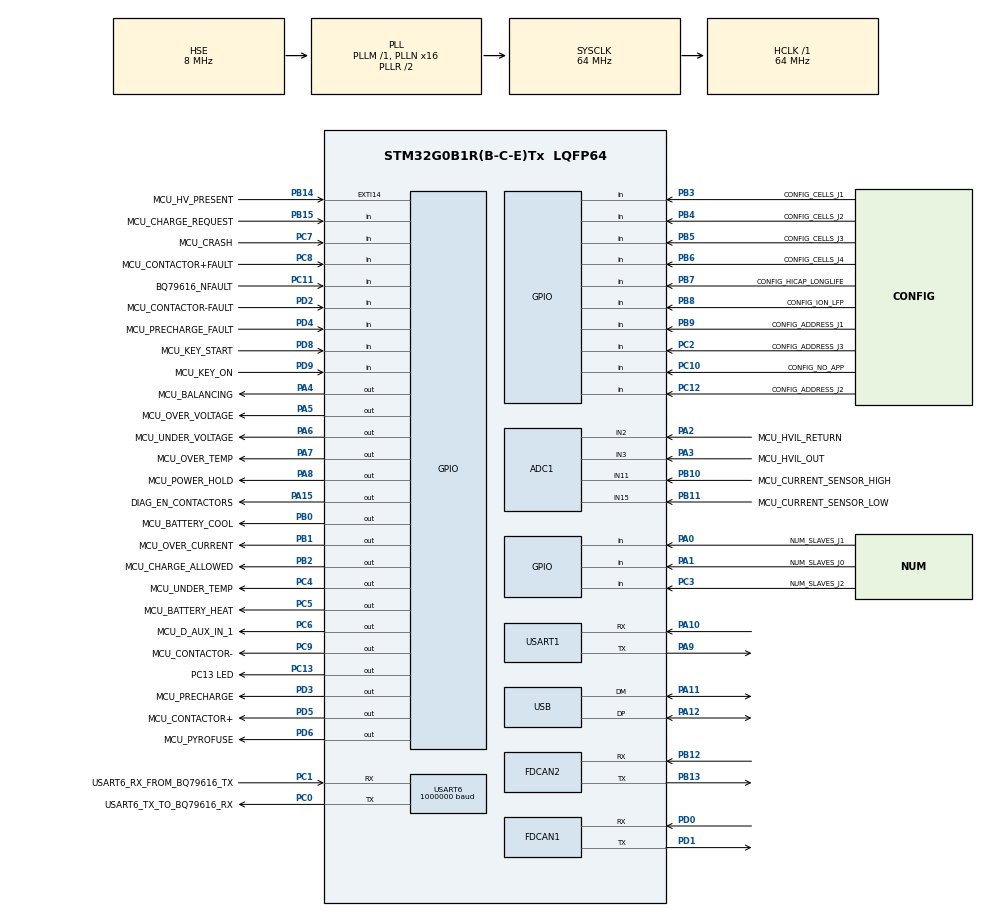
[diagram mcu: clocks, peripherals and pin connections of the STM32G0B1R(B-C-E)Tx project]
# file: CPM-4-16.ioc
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ADC1.NbrOfConversion=1
ADC1.NbrOfConversionFlag=0
ADC1.SelectedChannel=ADC_CHANNEL_2|ADC_CHANNEL_3|ADC_CHANNEL_11|ADC_CHANNEL_15
ADC1.Sequencer=NOT_FULLY_CONFIGURABLE
ADC1.master=1
Dma.Request0=USART1_TX
Dma.USART1_TX.0.Direction=DMA_MEMORY_TO_PERIPH
Dma.USART1_TX.0.EventEnable=DISABLE
Dma.USART1_TX.0.Instance=DMA1_Channel1
Dma.USART1_TX.0.MemDataAlignment=DMA_MDATAALIGN_BYTE
Dma.USART1_TX.0.MemInc=DMA_MINC_ENABLE
Dma.USART1_TX.0.Mode=DMA_NORMAL
Dma.USART1_TX.0.PeriphDataAlignment=DMA_PDATAALIGN_BYTE
Dma.USART1_TX.0.PeriphInc=DMA_PINC_DISABLE
Dma.USART1_TX.0.Polarity=HAL_DMAMUX_REQ_GEN_RISING
Dma.USART1_TX.0.Priority=DMA_PRIORITY_LOW
Dma.USART1_TX.0.RequestNumber=1
Dma.USART1_TX.0.SignalID=NONE
Dma.USART1_TX.0.SyncEnable=DISABLE
Dma.USART1_TX.0.SyncPolarity=HAL_DMAMUX_SYNC_NO_EVENT
Dma.USART1_TX.0.SyncRequestNumber=1
Dma.USART1_TX.0.SyncSignalID=NONE
FDCAN1.AutoRetransmission=ENABLE
FDCAN1.CalculateBaudRateNominal=500000
FDCAN1.CalculateTimeBitNominal=2000
FDCAN1.CalculateTimeQuantumNominal=125.0
FDCAN1.NominalPrescaler=8
FDCAN1.NominalSyncJumpWidth=2
FDCAN1.NominalTimeSeg1=13
FDCAN1.NominalTimeSeg2=2
FDCAN1.StdFiltersNbr=1
FDCAN2.CalculateBaudRateNominal=1333333
FDCAN2.CalculateTimeBitNominal=750
FDCAN2.CalculateTimeQuantumNominal=250.0
Mcu.Family=STM32G0
Mcu.Name=STM32G0B1R(B-C-E)Tx
Mcu.Package=LQFP64
NVIC.DMA1_Channel1_IRQn=true\:0\:0\:false\:false\:true\:false\:true\:true
NVIC.TIM2_IRQn=true\:3\:0\:true\:false\:true\:true\:true\:true
NVIC.TIM3_TIM4_IRQn=true\:3\:0\:true\:false\:true\:true\:true\:true
NVIC.USB_UCPD1_2_IRQn=true\:0\:0\:false\:false\:true\:true\:true\:true
NVIC.USART1_IRQn=true\:0\:0\:false\:false\:true\:true\:true\:true
PA0.GPIO_Label=NUM_SLAVES_J1
PA0.GPIO_PuPd=GPIO_PULLDOWN
PA0.Signal=GPIO_Input
PA1.GPIO_Label=NUM_SLAVES_J0
PA1.GPIO_PuPd=GPIO_PULLDOWN
PA1.Signal=GPIO_Input
PA10.Mode=Asynchronous
PA10.Signal=USART1_RX
PA11\ [PA9].Mode=Device
PA11\ [PA9].Signal=USB_DM
PA12\ [PA10].Mode=Device
PA12\ [PA10].Signal=USB_DP
PA13.Mode=Serial_Wire
PA13.Signal=SYS_SWDIO
PA14-BOOT0.Mode=Serial_Wire
PA14-BOOT0.Signal=SYS_SWCLK
PA15.GPIO_Label=DIAG_EN_CONTACTORS
PA15.Signal=GPIO_Output
PA2.GPIO_Label=MCU_HVIL_RETURN
PA2.Mode=IN2
PA2.Signal=ADC1_IN2
PA3.GPIO_Label=MCU_HVIL_OUT
PA3.Mode=IN3
PA3.Signal=ADC1_IN3
PA4.GPIO_Label=MCU_BALANCING
PA4.Signal=GPIO_Output
PA5.GPIO_Label=MCU_OVER_VOLTAGE
PA5.Signal=GPIO_Output
PA6.GPIO_Label=MCU_UNDER_VOLTAGE
PA6.Signal=GPIO_Output
PA7.GPIO_Label=MCU_OVER_TEMP
PA7.Signal=GPIO_Output
PA8.GPIO_Label=MCU_POWER_HOLD
PA8.Signal=GPIO_Output
PA9.Mode=Asynchronous
PA9.Signal=USART1_TX
PB0.GPIO_Label=MCU_BATTERY_COOL
PB0.Signal=GPIO_Output
PB1.GPIO_Label=MCU_OVER_CURRENT
PB1.Signal=GPIO_Output
PB10.GPIO_Label=MCU_CURRENT_SENSOR_HIGH
PB10.Mode=IN11
PB10.Signal=ADC1_IN11
PB11.GPIO_Label=MCU_CURRENT_SENSOR_LOW
PB11.Mode=IN15
PB11.Signal=ADC1_IN15
PB12.Mode=FDCAN_Activate
PB12.Signal=FDCAN2_RX
PB13.Mode=FDCAN_Activate
PB13.Signal=FDCAN2_TX
PB14.GPIO_Label=MCU_HV_PRESENT
PB14.Signal=GPXTI14
PB15.GPIO_Label=MCU_CHARGE_REQUEST
PB15.Signal=GPIO_Input
PB2.GPIO_Label=MCU_CHARGE_ALLOWED
PB2.Signal=GPIO_Output
PB3.GPIO_Label=CONFIG_CELLS_J1
PB3.GPIO_PuPd=GPIO_PULLDOWN
PB3.Signal=GPIO_Input
PB4.GPIO_Label=CONFIG_CELLS_J2
PB4.GPIO_PuPd=GPIO_PULLDOWN
PB4.Signal=GPIO_Input
PB5.GPIO_Label=CONFIG_CELLS_J3
PB5.GPIO_PuPd=GPIO_PULLDOWN
PB5.Signal=GPIO_Input
PB6.GPIO_Label=CONFIG_CELLS_J4
PB6.GPIO_PuPd=GPIO_PULLDOWN
PB6.Signal=GPIO_Input
PB7.GPIO_Label=CONFIG_HICAP_LONGLIFE
PB7.GPIO_PuPd=GPIO_PULLDOWN
PB7.Signal=GPIO_Input
PB8.GPIO_Label=CONFIG_ION_LFP
PB8.GPIO_PuPd=GPIO_PULLDOWN
PB8.Signal=GPIO_Input
PB9.GPIO_Label=CONFIG_ADDRESS_J1
PB9.GPIO_PuPd=GPIO_PULLDOWN
PB9.Signal=GPIO_Input
PC0.GPIO_Label=USART6_TX_TO_BQ79616_RX
PC0.Mode=Asynchronous
PC0.Signal=USART6_TX
PC1.GPIO_Label=USART6_RX_FROM_BQ79616_TX
PC1.Mode=Asynchronous
PC1.Signal=USART6_RX
PC10.GPIO_Label=CONFIG_NO_APP
PC10.GPIO_PuPd=GPIO_PULLDOWN
PC10.Signal=GPIO_Input
PC11.GPIO_Label=BQ79616_NFAULT
PC11.GPIO_PuPd=GPIO_PULLDOWN
PC11.Signal=GPIO_Input
PC12.GPIO_Label=CONFIG_ADDRESS_J2
PC12.GPIO_PuPd=GPIO_PULLDOWN
PC12.Signal=GPIO_Input
PC13.GPIO_Label=PC13 LED
PC13.Signal=GPIO_Output
PC14-OSC32_IN\ (PC14).Mode=LSE-External-Oscillator
PC14-OSC32_IN\ (PC14).Signal=RCC_OSC32_IN
PC15-OSC32_OUT\ (PC15).Mode=LSE-External-Oscillator
PC15-OSC32_OUT\ (PC15).Signal=RCC_OSC32_OUT
PC2.GPIO_Label=CONFIG_ADDRESS_J3
PC2.GPIO_Mode=GPIO_MODE_INPUT
PC2.GPIO_PuPd=GPIO_PULLDOWN
PC2.Signal=GPIO_Input
PC3.GPIO_Label=NUM_SLAVES_J2
PC3.GPIO_Mode=GPIO_MODE_INPUT
PC3.GPIO_PuPd=GPIO_PULLDOWN
PC3.Signal=GPIO_Input
PC4.GPIO_Label=MCU_UNDER_TEMP
PC4.Signal=GPIO_Output
PC5.GPIO_Label=MCU_BATTERY_HEAT
PC5.Signal=GPIO_Output
PC6.GPIO_Label=MCU_D_AUX_IN_1
PC6.Signal=GPIO_Output
PC7.GPIO_Label=MCU_CRASH
PC7.GPIO_Mode=GPIO_MODE_INPUT
PC7.GPIO_PuPd=GPIO_PULLDOWN
PC7.Signal=GPIO_Input
PC8.GPIO_Label=MCU_CONTACTOR+FAULT
PC8.GPIO_PuPd=GPIO_PULLUP
PC8.Signal=GPIO_Input
PC9.GPIO_Label=MCU_CONTACTOR-
PC9.Signal=GPIO_Output
PD0.Mode=FDCAN_Activate
PD0.Signal=FDCAN1_RX
PD1.Mode=FDCAN_Activate
PD1.Signal=FDCAN1_TX
PD2.GPIO_Label=MCU_CONTACTOR-FAULT
PD2.GPIO_PuPd=GPIO_PULLUP
PD2.Signal=GPIO_Input
PD3.GPIO_Label=MCU_PRECHARGE
PD3.Signal=GPIO_Output
PD4.GPIO_Label=MCU_PRECHARGE_FAULT
PD4.GPIO_PuPd=GPIO_PULLUP
PD4.Signal=GPIO_Input
PD5.GPIO_Label=MCU_CONTACTOR+
PD5.Signal=GPIO_Output
PD6.GPIO_Label=MCU_PYROFUSE
PD6.Signal=GPIO_Output
PD8.GPIO_Label=MCU_KEY_START
PD8.GPIO_PuPd=GPIO_PULLDOWN
PD8.Signal=GPIO_Input
PD9.GPIO_Label=MCU_KEY_ON
PD9.GPIO_PuPd=GPIO_PULLDOWN
PD9.Signal=GPIO_Input
PF0-OSC_IN\ (PF0).Mode=HSE-External-Oscillator
PF0-OSC_IN\ (PF0).Signal=RCC_OSC_IN
PF1-OSC_OUT\ (PF1).Mode=HSE-External-Oscillator
PF1-OSC_OUT\ (PF1).Signal=RCC_OSC_OUT
ProjectManager.HeapSize=0x200
ProjectManager.StackSize=0x400
ProjectManager.TargetToolchain=STM32CubeIDE
RCC.ADCFreq_Value=64000000
RCC.AHBFreq_Value=64000000
RCC.CortexFreq_Value=64000000
RCC.EXTERNAL_CLOCK_VALUE=48000
RCC.EnbaleCSS=true
RCC.FDCANCLockSelection=RCC_FDCANCLKSOURCE_PLL
RCC.HCLKFreq_Value=64000000
RCC.HSE_VALUE=8000000
RCC.HSI48_VALUE=48000000
RCC.HSI_VALUE=16000000
RCC.PLLN=16
RCC.PLLSourceVirtual=RCC_PLLSOURCE_HSE
RCC.SYSCLKFreq_VALUE=64000000
RCC.SYSCLKSource=RCC_SYSCLKSOURCE_PLLCLK
RCC.USBFreq_Value=48000000
RCC.VCOOutputFreq_Value=128000000
TIM2.Period=999
TIM2.Prescaler=63999
TIM3.Period=99
TIM3.Prescaler=6399
USART1.VirtualMode-Asynchronous=VM_ASYNC
USART6.BaudRate=1000000
USART6.VirtualMode-Asynchronous=VM_ASYNC
USB_DEVICE.CLASS_NAME_FS=CDC
USB_DEVICE.VirtualMode=Cdc
USB_DEVICE.VirtualModeFS=Cdc_FS
VP_SYS_VS_DBSignals.Mode=DisableDeadBatterySignals
VP_TIM2_VS_ClockSourceINT.Mode=Internal
VP_TIM3_VS_ClockSourceINT.Mode=Internal
VP_USB_DEVICE_VS_USB_DEVICE_CDC_FS.Mode=CDC_FS
board=custom

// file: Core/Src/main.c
/* USER CODE BEGIN Header */
/**
  ******************************************************************************
  * @file           : main.c
  * @brief          : Main program body
  ******************************************************************************
  * @attention
  *
  * Copyright (c) 2026 STMicroelectronics.
  * All rights reserved.
  *
  * This software is licensed under terms that can be found in the LICENSE file
  * in the root directory of this software component.
  * If no LICENSE file comes with this software, it is provided AS-IS.
  *
  ******************************************************************************
  */
/* USER CODE END Header */
#include "main.h"
#include "usb_device.h"

/* USER CODE BEGIN Includes */
#include "application.h"
#include "board.h"
/* USER CODE END Includes */

ADC_HandleTypeDef hadc1;

FDCAN_HandleTypeDef hfdcan1;
FDCAN_HandleTypeDef hfdcan2;

TIM_HandleTypeDef htim2;
TIM_HandleTypeDef htim3;

UART_HandleTypeDef huart1;
UART_HandleTypeDef huart6;
DMA_HandleTypeDef hdma_usart1_tx;

void SystemClock_Config(void);
static void MX_GPIO_Init(void);
static void MX_DMA_Init(void);
static void MX_FDCAN1_Init(void);
static void MX_FDCAN2_Init(void);
static void MX_USART1_UART_Init(void);
static void MX_ADC1_Init(void);
static void MX_USART6_UART_Init(void);
static void MX_TIM2_Init(void);
static void MX_TIM3_Init(void);

int main(void)
{

  /* MCU Configuration--------------------------------------------------------*/

  /* Reset of all peripherals, Initializes the Flash interface and the Systick. */
  HAL_Init();

  /* Configure the system clock */
  SystemClock_Config();

  /* Initialize all configured peripherals */
  MX_GPIO_Init();
  board_refresh_identity_from_jumpers();
  MX_DMA_Init();
  MX_FDCAN1_Init();
  MX_FDCAN2_Init();
  MX_USART1_UART_Init();
  MX_ADC1_Init();
  if (board_get_address() != BOARD_ADDR_MASTER)
  {
    MX_USART6_UART_Init();
  }
  MX_TIM2_Init();
  MX_TIM3_Init();
  MX_USB_Device_Init();
  /* USER CODE BEGIN 2 */
application_setup();

  /* USER CODE END 2 */

  /* Infinite loop */
  /* USER CODE BEGIN WHILE */
  while (1)
  {
	  application_loop();
    /* USER CODE END WHILE */

  }
}

void SystemClock_Config(void)
{
  RCC_OscInitTypeDef RCC_OscInitStruct = {0};
  RCC_ClkInitTypeDef RCC_ClkInitStruct = {0};

  /** Configure the main internal regulator output voltage
  */
  HAL_PWREx_ControlVoltageScaling(PWR_REGULATOR_VOLTAGE_SCALE1);

  /** Initializes the RCC Oscillators according to the specified parameters
  * in the RCC_OscInitTypeDef structure.
  */
  RCC_OscInitStruct.OscillatorType = RCC_OSCILLATORTYPE_HSE|RCC_OSCILLATORTYPE_HSI48;
  RCC_OscInitStruct.HSEState = RCC_HSE_ON;
  RCC_OscInitStruct.HSI48State = RCC_HSI48_ON;
  RCC_OscInitStruct.PLL.PLLState = RCC_PLL_ON;
  RCC_OscInitStruct.PLL.PLLSource = RCC_PLLSOURCE_HSE;
  RCC_OscInitStruct.PLL.PLLM = RCC_PLLM_DIV1;
  RCC_OscInitStruct.PLL.PLLN = 16;
  RCC_OscInitStruct.PLL.PLLP = RCC_PLLP_DIV2;
  RCC_OscInitStruct.PLL.PLLQ = RCC_PLLQ_DIV2;
  RCC_OscInitStruct.PLL.PLLR = RCC_PLLR_DIV2;
  if (HAL_RCC_OscConfig(&RCC_OscInitStruct) != HAL_OK)
  {
    Error_Handler();
  }

  /** Initializes the CPU, AHB and APB buses clocks
  */
  RCC_ClkInitStruct.ClockType = RCC_CLOCKTYPE_HCLK|RCC_CLOCKTYPE_SYSCLK
                              |RCC_CLOCKTYPE_PCLK1;
  RCC_ClkInitStruct.SYSCLKSource = RCC_SYSCLKSOURCE_PLLCLK;
  RCC_ClkInitStruct.AHBCLKDivider = RCC_SYSCLK_DIV1;
  RCC_ClkInitStruct.APB1CLKDivider = RCC_HCLK_DIV1;

  if (HAL_RCC_ClockConfig(&RCC_ClkInitStruct, FLASH_LATENCY_2) != HAL_OK)
  {
    Error_Handler();
  }

  /** Enables the Clock Security System
  */
  HAL_RCC_EnableCSS();
}

static void MX_ADC1_Init(void)
{

  ADC_ChannelConfTypeDef sConfig = {0};

  /** Configure the global features of the ADC (Clock, Resolution, Data Alignment and number of conversion)
  */
  hadc1.Instance = ADC1;
  hadc1.Init.ClockPrescaler = ADC_CLOCK_SYNC_PCLK_DIV2;
  hadc1.Init.Resolution = ADC_RESOLUTION_12B;
  hadc1.Init.DataAlign = ADC_DATAALIGN_RIGHT;
  hadc1.Init.ScanConvMode = ADC_SCAN_SEQ_FIXED;
  hadc1.Init.EOCSelection = ADC_EOC_SINGLE_CONV;
  hadc1.Init.LowPowerAutoWait = DISABLE;
  hadc1.Init.LowPowerAutoPowerOff = DISABLE;
  hadc1.Init.ContinuousConvMode = DISABLE;
  hadc1.Init.NbrOfConversion = 1;
  hadc1.Init.DiscontinuousConvMode = DISABLE;
  hadc1.Init.ExternalTrigConv = ADC_SOFTWARE_START;
  hadc1.Init.ExternalTrigConvEdge = ADC_EXTERNALTRIGCONVEDGE_NONE;
  hadc1.Init.DMAContinuousRequests = DISABLE;
  hadc1.Init.Overrun = ADC_OVR_DATA_PRESERVED;
  hadc1.Init.SamplingTimeCommon1 = ADC_SAMPLETIME_1CYCLE_5;
  hadc1.Init.OversamplingMode = DISABLE;
  hadc1.Init.TriggerFrequencyMode = ADC_TRIGGER_FREQ_HIGH;
  if (HAL_ADC_Init(&hadc1) != HAL_OK)
  {
    Error_Handler();
  }

  /** Configure Regular Channel
  */
  sConfig.Channel = ADC_CHANNEL_2;
  sConfig.Rank = ADC_RANK_CHANNEL_NUMBER;
  if (HAL_ADC_ConfigChannel(&hadc1, &sConfig) != HAL_OK)
  {
    Error_Handler();
  }

  /** Configure Regular Channel
  */
  sConfig.Channel = ADC_CHANNEL_3;
  if (HAL_ADC_ConfigChannel(&hadc1, &sConfig) != HAL_OK)
  {
    Error_Handler();
  }

  /** Configure Regular Channel
  */
  sConfig.Channel = ADC_CHANNEL_11;
  if (HAL_ADC_ConfigChannel(&hadc1, &sConfig) != HAL_OK)
  {
    Error_Handler();
  }

  /** Configure Regular Channel
  */
  sConfig.Channel = ADC_CHANNEL_15;
  if (HAL_ADC_ConfigChannel(&hadc1, &sConfig) != HAL_OK)
  {
    Error_Handler();
  }

}

static void MX_FDCAN1_Init(void)
{

  hfdcan1.Instance = FDCAN1;
  hfdcan1.Init.ClockDivider = FDCAN_CLOCK_DIV1;
  hfdcan1.Init.FrameFormat = FDCAN_FRAME_CLASSIC;
  hfdcan1.Init.Mode = FDCAN_MODE_NORMAL;
  hfdcan1.Init.AutoRetransmission = ENABLE;
  hfdcan1.Init.TransmitPause = DISABLE;
  hfdcan1.Init.ProtocolException = DISABLE;
  hfdcan1.Init.NominalPrescaler = 8;
  hfdcan1.Init.NominalSyncJumpWidth = 2;
  hfdcan1.Init.NominalTimeSeg1 = 13;
  hfdcan1.Init.NominalTimeSeg2 = 2;
  hfdcan1.Init.DataPrescaler = 1;
  hfdcan1.Init.DataSyncJumpWidth = 1;
  hfdcan1.Init.DataTimeSeg1 = 1;
  hfdcan1.Init.DataTimeSeg2 = 1;
  hfdcan1.Init.StdFiltersNbr = 1;
  hfdcan1.Init.ExtFiltersNbr = 0;
  hfdcan1.Init.TxFifoQueueMode = FDCAN_TX_FIFO_OPERATION;
  if (HAL_FDCAN_Init(&hfdcan1) != HAL_OK)
  {
    Error_Handler();
  }

}

static void MX_FDCAN2_Init(void)
{

  hfdcan2.Instance = FDCAN2;
  hfdcan2.Init.ClockDivider = FDCAN_CLOCK_DIV1;
  hfdcan2.Init.FrameFormat = FDCAN_FRAME_CLASSIC;
  hfdcan2.Init.Mode = FDCAN_MODE_NORMAL;
  hfdcan2.Init.AutoRetransmission = ENABLE;
  hfdcan2.Init.TransmitPause = DISABLE;
  hfdcan2.Init.ProtocolException = DISABLE;
  hfdcan2.Init.NominalPrescaler = 8;
  hfdcan2.Init.NominalSyncJumpWidth = 2;
  hfdcan2.Init.NominalTimeSeg1 = 13;
  hfdcan2.Init.NominalTimeSeg2 = 2;
  hfdcan2.Init.DataPrescaler = 1;
  hfdcan2.Init.DataSyncJumpWidth = 1;
  hfdcan2.Init.DataTimeSeg1 = 1;
  hfdcan2.Init.DataTimeSeg2 = 1;
  hfdcan2.Init.StdFiltersNbr = 3;
  hfdcan2.Init.ExtFiltersNbr = 0;
  hfdcan2.Init.TxFifoQueueMode = FDCAN_TX_FIFO_OPERATION;
  if (HAL_FDCAN_Init(&hfdcan2) != HAL_OK)
  {
    Error_Handler();
  }

}

static void MX_TIM2_Init(void)
{

  TIM_ClockConfigTypeDef sClockSourceConfig = {0};
  TIM_MasterConfigTypeDef sMasterConfig = {0};

  htim2.Instance = TIM2;
  htim2.Init.Prescaler = 63999;
  htim2.Init.CounterMode = TIM_COUNTERMODE_UP;
  htim2.Init.Period = 999;
  htim2.Init.ClockDivision = TIM_CLOCKDIVISION_DIV1;
  htim2.Init.AutoReloadPreload = TIM_AUTORELOAD_PRELOAD_DISABLE;
  if (HAL_TIM_Base_Init(&htim2) != HAL_OK)
  {
    Error_Handler();
  }
  sClockSourceConfig.ClockSource = TIM_CLOCKSOURCE_INTERNAL;
  if (HAL_TIM_ConfigClockSource(&htim2, &sClockSourceConfig) != HAL_OK)
  {
    Error_Handler();
  }
  sMasterConfig.MasterOutputTrigger = TIM_TRGO_RESET;
  sMasterConfig.MasterSlaveMode = TIM_MASTERSLAVEMODE_DISABLE;
  if (HAL_TIMEx_MasterConfigSynchronization(&htim2, &sMasterConfig) != HAL_OK)
  {
    Error_Handler();
  }

}

static void MX_TIM3_Init(void)
{

  TIM_ClockConfigTypeDef sClockSourceConfig = {0};
  TIM_MasterConfigTypeDef sMasterConfig = {0};

  htim3.Instance = TIM3;
  htim3.Init.Prescaler = 6399;
  htim3.Init.CounterMode = TIM_COUNTERMODE_UP;
  htim3.Init.Period = 99;
  htim3.Init.ClockDivision = TIM_CLOCKDIVISION_DIV1;
  htim3.Init.AutoReloadPreload = TIM_AUTORELOAD_PRELOAD_DISABLE;
  if (HAL_TIM_Base_Init(&htim3) != HAL_OK)
  {
    Error_Handler();
  }
  sClockSourceConfig.ClockSource = TIM_CLOCKSOURCE_INTERNAL;
  if (HAL_TIM_ConfigClockSource(&htim3, &sClockSourceConfig) != HAL_OK)
  {
    Error_Handler();
  }
  sMasterConfig.MasterOutputTrigger = TIM_TRGO_RESET;
  sMasterConfig.MasterSlaveMode = TIM_MASTERSLAVEMODE_DISABLE;
  if (HAL_TIMEx_MasterConfigSynchronization(&htim3, &sMasterConfig) != HAL_OK)
  {
    Error_Handler();
  }

}

static void MX_USART1_UART_Init(void)
{

  huart1.Instance = USART1;
  huart1.Init.BaudRate = 115200;
  huart1.Init.WordLength = UART_WORDLENGTH_8B;
  huart1.Init.StopBits = UART_STOPBITS_1;
  huart1.Init.Parity = UART_PARITY_NONE;
  huart1.Init.Mode = UART_MODE_TX_RX;
  huart1.Init.HwFlowCtl = UART_HWCONTROL_NONE;
  huart1.Init.OverSampling = UART_OVERSAMPLING_16;
  huart1.Init.OneBitSampling = UART_ONE_BIT_SAMPLE_DISABLE;
  huart1.Init.ClockPrescaler = UART_PRESCALER_DIV1;
  huart1.AdvancedInit.AdvFeatureInit = UART_ADVFEATURE_NO_INIT;
  if (HAL_UART_Init(&huart1) != HAL_OK)
  {
    Error_Handler();
  }
  if (HAL_UARTEx_SetTxFifoThreshold(&huart1, UART_TXFIFO_THRESHOLD_1_8) != HAL_OK)
  {
    Error_Handler();
  }
  if (HAL_UARTEx_SetRxFifoThreshold(&huart1, UART_RXFIFO_THRESHOLD_1_8) != HAL_OK)
  {
    Error_Handler();
  }
  if (HAL_UARTEx_DisableFifoMode(&huart1) != HAL_OK)
  {
    Error_Handler();
  }

}

static void MX_USART6_UART_Init(void)
{

  huart6.Instance = USART6;
  huart6.Init.BaudRate = 1000000;
  huart6.Init.WordLength = UART_WORDLENGTH_8B;
  huart6.Init.StopBits = UART_STOPBITS_1;
  huart6.Init.Parity = UART_PARITY_NONE;
  huart6.Init.Mode = UART_MODE_TX_RX;
  huart6.Init.HwFlowCtl = UART_HWCONTROL_NONE;
  huart6.Init.OverSampling = UART_OVERSAMPLING_16;
  huart6.Init.OneBitSampling = UART_ONE_BIT_SAMPLE_DISABLE;
  huart6.Init.ClockPrescaler = UART_PRESCALER_DIV1;
  huart6.AdvancedInit.AdvFeatureInit = UART_ADVFEATURE_NO_INIT;
  if (HAL_UART_Init(&huart6) != HAL_OK)
  {
    Error_Handler();
  }

}

static void MX_DMA_Init(void)
{

  /* DMA controller clock enable */
  __HAL_RCC_DMA1_CLK_ENABLE();

  /* DMA interrupt init */
  /* DMA1_Channel1_IRQn interrupt configuration */
  HAL_NVIC_SetPriority(DMA1_Channel1_IRQn, 0, 0);
  HAL_NVIC_EnableIRQ(DMA1_Channel1_IRQn);

}

static void MX_GPIO_Init(void)
{
  GPIO_InitTypeDef GPIO_InitStruct = {0};

  /* GPIO Ports Clock Enable */
  __HAL_RCC_GPIOC_CLK_ENABLE();
  __HAL_RCC_GPIOF_CLK_ENABLE();
  __HAL_RCC_GPIOA_CLK_ENABLE();
  __HAL_RCC_GPIOB_CLK_ENABLE();
  __HAL_RCC_GPIOD_CLK_ENABLE();

  /*Configure GPIO pin Output Level */
  HAL_GPIO_WritePin(GPIOC, PC13_LED_Pin|MCU_UNDER_TEMP_Pin|MCU_BATTERY_HEAT_Pin|MCU_D_AUX_IN_1_Pin
                          |MCU_CONTACTOR__Pin, GPIO_PIN_RESET);

  /*Configure GPIO pin Output Level */
  HAL_GPIO_WritePin(GPIOA, MCU_BALANCING_Pin|MCU_OVER_VOLTAGE_Pin|MCU_UNDER_VOLTAGE_Pin|MCU_OVER_TEMP_Pin
                          |MCU_POWER_HOLD_Pin|DIAG_EN_CONTACTORS_Pin, GPIO_PIN_RESET);

  /*Configure GPIO pin Output Level */
  HAL_GPIO_WritePin(GPIOB, MCU_BATTERY_COOL_Pin|MCU_OVER_CURRENT_Pin|MCU_CHARGE_ALLOWED_Pin, GPIO_PIN_RESET);

  /*Configure GPIO pin Output Level */
  HAL_GPIO_WritePin(GPIOD, MCU_PRECHARGE_Pin|MCU_CONTACTOR_D5_Pin|MCU_PYROFUSE_Pin, GPIO_PIN_RESET);

  /*Configure GPIO pins : BQ79616_NFAULT_Pin MCU_CRASH_Pin */
  GPIO_InitStruct.Pin = BQ79616_NFAULT_Pin|MCU_CRASH_Pin;
  GPIO_InitStruct.Mode = GPIO_MODE_INPUT;
  GPIO_InitStruct.Pull = GPIO_PULLDOWN;
  HAL_GPIO_Init(GPIOC, &GPIO_InitStruct);

  /*Configure GPIO pins : CONFIG_ADDRESS_J2_Pin CONFIG_ADDRESS_J3_Pin NUM_SLAVES_J2_Pin CONFIG_NO_APP_Pin */
  GPIO_InitStruct.Pin = CONFIG_ADDRESS_J2_Pin|CONFIG_ADDRESS_J3_Pin|NUM_SLAVES_J2_Pin|CONFIG_NO_APP_Pin;
  GPIO_InitStruct.Mode = GPIO_MODE_INPUT;
  GPIO_InitStruct.Pull = GPIO_PULLDOWN;
  HAL_GPIO_Init(GPIOC, &GPIO_InitStruct);

  /*Configure GPIO pins : PC13_LED_Pin MCU_UNDER_TEMP_Pin MCU_BATTERY_HEAT_Pin MCU_D_AUX_IN_1_Pin
                           MCU_CONTACTOR__Pin */
  GPIO_InitStruct.Pin = PC13_LED_Pin|MCU_UNDER_TEMP_Pin|MCU_BATTERY_HEAT_Pin|MCU_D_AUX_IN_1_Pin
                          |MCU_CONTACTOR__Pin;
  GPIO_InitStruct.Mode = GPIO_MODE_OUTPUT_PP;
  GPIO_InitStruct.Pull = GPIO_NOPULL;
  GPIO_InitStruct.Speed = GPIO_SPEED_FREQ_LOW;
  HAL_GPIO_Init(GPIOC, &GPIO_InitStruct);

  /*Configure GPIO pins : NUM_SLAVES_J1_Pin NUM_SLAVES_J0_Pin */
  GPIO_InitStruct.Pin = NUM_SLAVES_J1_Pin|NUM_SLAVES_J0_Pin;
  GPIO_InitStruct.Mode = GPIO_MODE_INPUT;
  GPIO_InitStruct.Pull = GPIO_PULLDOWN;
  HAL_GPIO_Init(GPIOA, &GPIO_InitStruct);

  /*Configure GPIO pins : MCU_BALANCING_Pin MCU_OVER_VOLTAGE_Pin MCU_UNDER_VOLTAGE_Pin MCU_OVER_TEMP_Pin
                           MCU_POWER_HOLD_Pin DIAG_EN_CONTACTORS_Pin */
  GPIO_InitStruct.Pin = MCU_BALANCING_Pin|MCU_OVER_VOLTAGE_Pin|MCU_UNDER_VOLTAGE_Pin|MCU_OVER_TEMP_Pin
                          |MCU_POWER_HOLD_Pin|DIAG_EN_CONTACTORS_Pin;
  GPIO_InitStruct.Mode = GPIO_MODE_OUTPUT_PP;
  GPIO_InitStruct.Pull = GPIO_NOPULL;
  GPIO_InitStruct.Speed = GPIO_SPEED_FREQ_LOW;
  HAL_GPIO_Init(GPIOA, &GPIO_InitStruct);

  /*Configure GPIO pins : MCU_BATTERY_COOL_Pin MCU_OVER_CURRENT_Pin MCU_CHARGE_ALLOWED_Pin */
  GPIO_InitStruct.Pin = MCU_BATTERY_COOL_Pin|MCU_OVER_CURRENT_Pin|MCU_CHARGE_ALLOWED_Pin;
  GPIO_InitStruct.Mode = GPIO_MODE_OUTPUT_PP;
  GPIO_InitStruct.Pull = GPIO_NOPULL;
  GPIO_InitStruct.Speed = GPIO_SPEED_FREQ_LOW;
  HAL_GPIO_Init(GPIOB, &GPIO_InitStruct);

  /*Configure GPIO pin : MCU_HV_PRESENT_Pin */
  GPIO_InitStruct.Pin = MCU_HV_PRESENT_Pin;
  GPIO_InitStruct.Mode = GPIO_MODE_IT_RISING;
  GPIO_InitStruct.Pull = GPIO_NOPULL;
  HAL_GPIO_Init(MCU_HV_PRESENT_GPIO_Port, &GPIO_InitStruct);

  /*Configure GPIO pin : MCU_CHARGE_REQUEST_Pin */
  GPIO_InitStruct.Pin = MCU_CHARGE_REQUEST_Pin;
  GPIO_InitStruct.Mode = GPIO_MODE_INPUT;
  GPIO_InitStruct.Pull = GPIO_NOPULL;
  HAL_GPIO_Init(MCU_CHARGE_REQUEST_GPIO_Port, &GPIO_InitStruct);

  /*Configure GPIO pins : MCU_KEY_START_Pin MCU_KEY_ON_Pin */
  GPIO_InitStruct.Pin = MCU_KEY_START_Pin|MCU_KEY_ON_Pin;
  GPIO_InitStruct.Mode = GPIO_MODE_INPUT;
  GPIO_InitStruct.Pull = GPIO_PULLDOWN;
  HAL_GPIO_Init(GPIOD, &GPIO_InitStruct);

  /*Configure GPIO pin : MCU_CONTACTOR_FAULT_Pin */
  GPIO_InitStruct.Pin = MCU_CONTACTOR_FAULT_Pin;
  GPIO_InitStruct.Mode = GPIO_MODE_INPUT;
  GPIO_InitStruct.Pull = GPIO_PULLUP;
  HAL_GPIO_Init(MCU_CONTACTOR_FAULT_GPIO_Port, &GPIO_InitStruct);

  /*Configure GPIO pins : MCU_CONTACTOR_FAULTD2_Pin MCU_PRECHARGE_FAULT_Pin */
  GPIO_InitStruct.Pin = MCU_CONTACTOR_FAULTD2_Pin|MCU_PRECHARGE_FAULT_Pin;
  GPIO_InitStruct.Mode = GPIO_MODE_INPUT;
  GPIO_InitStruct.Pull = GPIO_PULLUP;
  HAL_GPIO_Init(GPIOD, &GPIO_InitStruct);

  /*Configure GPIO pins : MCU_PRECHARGE_Pin MCU_CONTACTOR_D5_Pin MCU_PYROFUSE_Pin */
  GPIO_InitStruct.Pin = MCU_PRECHARGE_Pin|MCU_CONTACTOR_D5_Pin|MCU_PYROFUSE_Pin;
  GPIO_InitStruct.Mode = GPIO_MODE_OUTPUT_PP;
  GPIO_InitStruct.Pull = GPIO_NOPULL;
  GPIO_InitStruct.Speed = GPIO_SPEED_FREQ_LOW;
  HAL_GPIO_Init(GPIOD, &GPIO_InitStruct);

  /*Configure GPIO pins : CONFIG_CELLS_J1_Pin CONFIG_CELLS_J2_Pin CONFIG_CELLS_J3_Pin CONFIG_CELLS_J4_Pin
                           CONFIG_HICAP_LONGLIFE_Pin CONFIG_ION_LFP_Pin CONFIG_ADDRESS_J1_Pin */
  GPIO_InitStruct.Pin = CONFIG_CELLS_J1_Pin|CONFIG_CELLS_J2_Pin|CONFIG_CELLS_J3_Pin|CONFIG_CELLS_J4_Pin
                          |CONFIG_HICAP_LONGLIFE_Pin|CONFIG_ION_LFP_Pin|CONFIG_ADDRESS_J1_Pin;
  GPIO_InitStruct.Mode = GPIO_MODE_INPUT;
  GPIO_InitStruct.Pull = GPIO_PULLDOWN;
  HAL_GPIO_Init(GPIOB, &GPIO_InitStruct);

}

void Error_Handler(void)
{
  __disable_irq();
  while (1)
  {
  }
}
